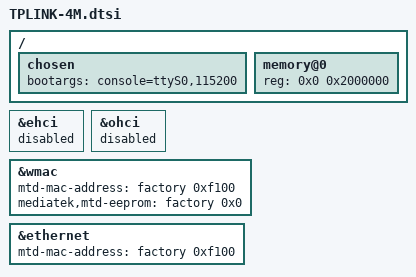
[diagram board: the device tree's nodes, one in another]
#include "mt7628an.dtsi"

/ {
	chosen {
		bootargs = "console=ttyS0,115200";
	};

	memory@0 {
		device_type = "memory";
		reg = <0x0 0x2000000>;
	};
};

&ehci {
	status = "disabled";
};

&ohci {
	status = "disabled";
};

&wmac {
	status = "okay";
	mtd-mac-address = <&factory 0xf100>;
	mediatek,mtd-eeprom = <&factory 0x0>;
};

&ethernet {
	mtd-mac-address = <&factory 0xf100>;
};
